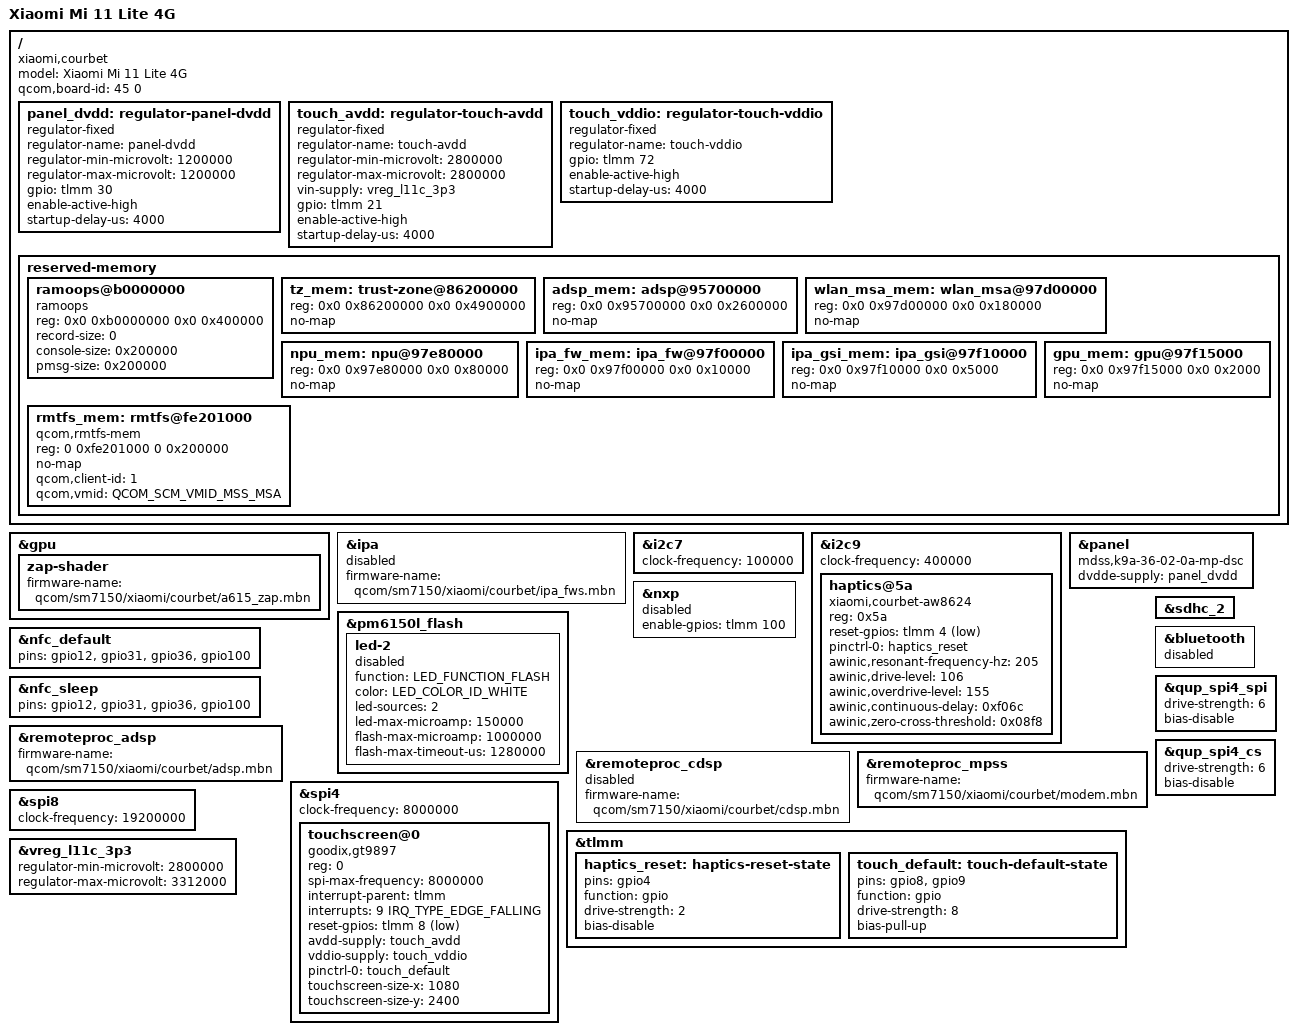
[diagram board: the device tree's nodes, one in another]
// SPDX-License-Identifier: BSD-3-Clause
/*
 * Copyright (c) 2024, Danila Tikhonov <danila@jiaxyga.com>
 */

/dts-v1/;

#include "sm7150-xiaomi-common.dtsi"

/delete-node/ &{/reserved-memory/ramoops@9d800000};

/delete-node/ &adsp_mem;
/delete-node/ &wlan_msa_mem;
/delete-node/ &npu_mem;
/delete-node/ &ipa_fw_mem;
/delete-node/ &ipa_gsi_mem;
/delete-node/ &gpu_mem;
/delete-node/ &tz_mem;

/ {
	model = "Xiaomi Mi 11 Lite 4G";
	compatible = "xiaomi,courbet", "qcom,sm7150";

	qcom,board-id = <45 0>;

	panel_dvdd: regulator-panel-dvdd {
		compatible = "regulator-fixed";
		regulator-name = "panel-dvdd";
		regulator-min-microvolt = <1200000>;
		regulator-max-microvolt = <1200000>;
		gpio = <&tlmm 30 GPIO_ACTIVE_HIGH>;
		enable-active-high;
		startup-delay-us = <4000>;
	};

	touch_avdd: regulator-touch-avdd {
		compatible = "regulator-fixed";
		regulator-name = "touch-avdd";
		regulator-min-microvolt = <2800000>;
		regulator-max-microvolt = <2800000>;
		vin-supply = <&vreg_l11c_3p3>;
		gpio = <&tlmm 21 GPIO_ACTIVE_HIGH>;
		enable-active-high;
		startup-delay-us = <4000>;
	};

	touch_vddio: regulator-touch-vddio {
		compatible = "regulator-fixed";
		regulator-name = "touch-vddio";
		gpio = <&tlmm 72 GPIO_ACTIVE_HIGH>;
		enable-active-high;
		startup-delay-us = <4000>;
	};

	reserved-memory {
		/* Match the owner's Android ramoops layout for recovery logs. */
		ramoops@b0000000 {
			compatible = "ramoops";
			reg = <0x0 0xb0000000 0x0 0x400000>;
			record-size = <0>;
			console-size = <0x200000>;
			pmsg-size = <0x200000>;
		};

		tz_mem: trust-zone@86200000 {
			reg = <0x0 0x86200000 0x0 0x4900000>;
			no-map;
		};

		adsp_mem: adsp@95700000 {
			reg = <0x0 0x95700000 0x0 0x2600000>;
			no-map;
		};

		wlan_msa_mem: wlan_msa@97d00000 {
			reg = <0x0 0x97d00000 0x0 0x180000>;
			no-map;
		};

		npu_mem: npu@97e80000 {
			reg = <0x0 0x97e80000 0x0 0x80000>;
			no-map;
		};

		ipa_fw_mem: ipa_fw@97f00000 {
			reg = <0x0 0x97f00000 0x0 0x10000>;
			no-map;
		};

		ipa_gsi_mem: ipa_gsi@97f10000 {
			reg = <0x0 0x97f10000 0x0 0x5000>;
			no-map;
		};

		gpu_mem: gpu@97f15000 {
			reg = <0x0 0x97f15000 0x0 0x2000>;
			no-map;
		};

		rmtfs_mem: rmtfs@fe201000 {
			compatible = "qcom,rmtfs-mem";
			reg = <0 0xfe201000 0 0x200000>;
			no-map;

			qcom,client-id = <1>;
			qcom,vmid = <QCOM_SCM_VMID_MSS_MSA>;
		};
	};
};

&gpu {
	zap-shader {
		firmware-name = "qcom/sm7150/xiaomi/courbet/a615_zap.mbn";
	};
};

&ipa {
	firmware-name = "qcom/sm7150/xiaomi/courbet/ipa_fws.mbn";
};

&i2c7 {
	clock-frequency = <100000>;
	status = "okay";

	/* qcom,pm8008 (pmic) @ 8 */
	/* qcom,pm8008 (pmic) @ 9 */
	/* tfa,tfa98xx (speaker amplifier) @ 34 */
	/* tfa,tfa98xx (speaker amplifier) @ 35 */
	/* st,fts (ts) @ 49 */
	/* goodix,gt9886 (ts) @ 5d */
};

&i2c9 {
	clock-frequency = <400000>;
	status = "okay";

	/* qcom,fsa4480 (usb switcher) @ 42 */
	haptics@5a {
		compatible = "xiaomi,courbet-aw8624";
		reg = <0x5a>;
		reset-gpios = <&tlmm 4 GPIO_ACTIVE_LOW>;
		pinctrl-names = "default";
		pinctrl-0 = <&haptics_reset>;
		awinic,resonant-frequency-hz = <205>;
		awinic,drive-level = <106>;
		awinic,overdrive-level = <155>;
		awinic,continuous-delay = <0xf06c>;
		awinic,zero-cross-threshold = <0x08f8>;
	};
	/* ti,bq25968 (charger) @ 66 */
};

/* The populated rear flash output is described in sm7150-xiaomi-common.dtsi. */
&pm6150l_flash {
	status = "okay";

	/* The second output reports a short/open fault on the tested handset. */
	led-2 {
		function = LED_FUNCTION_FLASH;
		color = <LED_COLOR_ID_WHITE>;
		led-sources = <2>;
		led-max-microamp = <150000>;
		flash-max-microamp = <1000000>;
		flash-max-timeout-us = <1280000>;
		status = "disabled";
	};
};

&panel {
	dvdde-supply = <&panel_dvdd>;
	compatible = "mdss,k9a-36-02-0a-mp-dsc";
};

&nfc_default {
	pins = "gpio12", "gpio31", "gpio36", "gpio100";
};

&nfc_sleep {
	pins = "gpio12", "gpio31", "gpio36", "gpio100";
};

&nxp {
	enable-gpios = <&tlmm 100 GPIO_ACTIVE_HIGH>;
};

&remoteproc_adsp {
	/*
	 * Hosts the Snapdragon Sensor Core. Userspace must serve both the root
	 * PD and sensorspd over FastRPC, or the sensors PD watchdog fires.
	 */
	firmware-name = "qcom/sm7150/xiaomi/courbet/adsp.mbn";
	status = "okay";
};

&remoteproc_cdsp {
	firmware-name = "qcom/sm7150/xiaomi/courbet/cdsp.mbn";
};

&remoteproc_mpss {
	firmware-name = "qcom/sm7150/xiaomi/courbet/modem.mbn";
};

&sdhc_2 {
	status = "okay";
};

&spi4 {
	clock-frequency = <8000000>;
	status = "okay";

	touchscreen@0 {
		compatible = "goodix,gt9897";
		reg = <0>;
		spi-max-frequency = <8000000>;
		interrupt-parent = <&tlmm>;
		interrupts = <9 IRQ_TYPE_EDGE_FALLING>;
		reset-gpios = <&tlmm 8 GPIO_ACTIVE_LOW>;
		avdd-supply = <&touch_avdd>;
		vddio-supply = <&touch_vddio>;
		pinctrl-names = "default";
		pinctrl-0 = <&touch_default>;
		touchscreen-size-x = <1080>;
		touchscreen-size-y = <2400>;
	};
};

&spi8 {
	clock-frequency = <19200000>;
	status = "okay";

	/* ir-spi @ 0 */
};


/* Initial RAM-resident Linux bring-up: keep unsupported subsystems off. */
&ipa {
	status = "disabled";
};

&remoteproc_cdsp {
	status = "disabled";
};

/* MPSS hosts the WLAN protection domain; retain it for ath10k. */

&bluetooth {
	status = "disabled";
};

&nxp {
	status = "disabled";
};

&qup_spi4_spi {
	drive-strength = <6>;
	bias-disable;
};

&qup_spi4_cs {
	drive-strength = <6>;
	bias-disable;
};

&tlmm {
	haptics_reset: haptics-reset-state {
		pins = "gpio4";
		function = "gpio";
		drive-strength = <2>;
		bias-disable;
	};

	touch_default: touch-default-state {
		pins = "gpio8", "gpio9";
		function = "gpio";
		drive-strength = <8>;
		bias-pull-up;
	};
};

/* The courbet Android board supplies touch AVDD from L11C at 2.8 V. */
&vreg_l11c_3p3 {
	regulator-min-microvolt = <2800000>;
	regulator-max-microvolt = <3312000>;
};
